# STM32G491 register map
File version: 2.8
CPU: CM4 r0p1, little endian, MPU, FPU, 4 interrupt priority bits
Registers are 32-bit, read-write, reset 0x0 unless marked. A register's access mark holds for its fields unless they carry their own. Offsets are from the block's base; [hi:lo] are bit positions; {n}, {i} and the like mark numbered series.

## FMAC — Filter Math Accelerator
Base 0x40021400
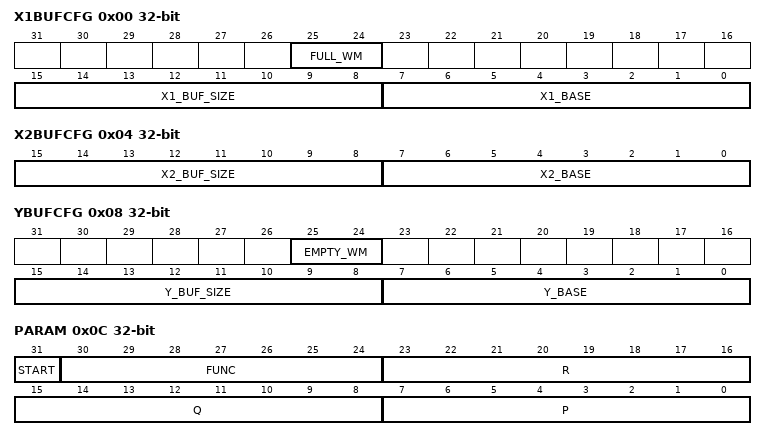
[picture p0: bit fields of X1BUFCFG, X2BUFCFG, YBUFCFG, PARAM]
0x00 X1BUFCFG — FMAC X1 Buffer Configuration register
  [25:24] FULL_WM, [15:8] X1_BUF_SIZE, [7:0] X1_BASE
0x04 X2BUFCFG — FMAC X2 Buffer Configuration register
  [15:8] X2_BUF_SIZE — X1_BUF_SIZE
  [7:0] X2_BASE — X1_BASE
0x08 YBUFCFG — FMAC Y Buffer Configuration register
  [25:24] EMPTY_WM
  [15:8] Y_BUF_SIZE — X1_BUF_SIZE
  [7:0] Y_BASE — X1_BASE
0x0C PARAM — FMAC Parameter register
  [31] START, [30:24] FUNC, [23:16] R, [15:8] Q, [7:0] P
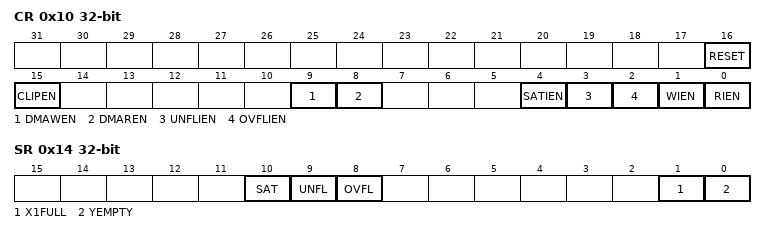
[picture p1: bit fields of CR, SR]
0x10 CR — FMAC Control register
  [16] RESET, [15] CLIPEN, [9] DMAWEN, [8] DMAREN, [4] SATIEN, [3] UNFLIEN, [2] OVFLIEN, [1] WIEN, [0] RIEN
0x14 SR ro — FMAC Status register
  [10] SAT, [9] UNFL, [8] OVFL, [1] X1FULL, [0] YEMPTY
0x18 WDATA wo — FMAC Write Data register
  [15:0] WDATA
0x1C RDATA ro — FMAC Read Data register
  [15:0] RDATA

## IWDG — WinWATCHDOG
Base 0x40003000
0x00 KR 16-bit wo — Key register
  [15:0] KEY — Key value (write only, read 0x0000)
    0x5555=Unlock (Enable access to PR, RLR and WINR registers); 0xAAAA=Feed watchdog with RLR register value; 0xCCCC=Start the watchdog
0x04 PR 16-bit — Prescaler register
  [2:0] PR — Prescaler divider
    0=DivideBy4 (Divider /4); 1=DivideBy8 (Divider /8); 2=DivideBy16 (Divider /16); 3=DivideBy32 (Divider /32); 4=DivideBy64 (Divider /64); 5=DivideBy128 (Divider /128); other=DivideBy256 (Divider /256)
0x08 RLR 16-bit reset 0xFFF — Reload register
  [11:0] RL — Watchdog counter reload value
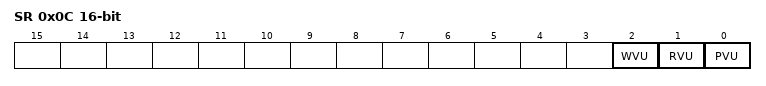
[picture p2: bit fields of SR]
0x0C SR 16-bit ro — Status register
  [2] WVU — Watchdog counter window value update
  [1] RVU — Watchdog counter reload value update
  [0] PVU — Watchdog prescaler value update
0x10 WINR 16-bit reset 0xFFF — Window register
  [11:0] WIN — Watchdog counter window value

## PWR — Power control
Base 0x40007000
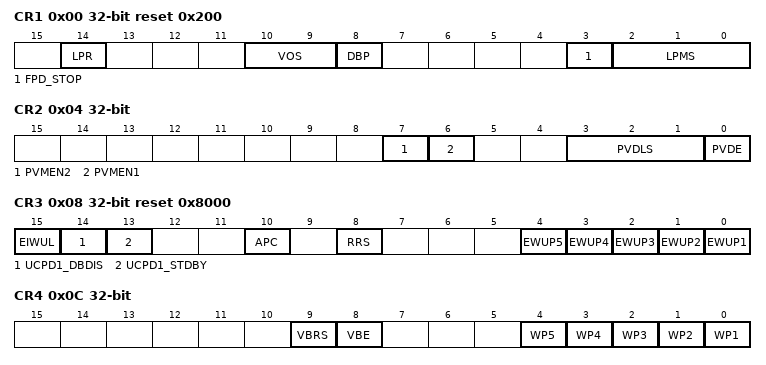
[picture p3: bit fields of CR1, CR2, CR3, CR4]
0x00 CR1 reset 0x200 — Power control register 1
  [14] LPR — Low-power run
  [10:9] VOS — Voltage scaling range selection
  [8] DBP — Disable backup domain write protection
  [3] FPD_STOP
  [2:0] LPMS — Low-power mode selection
0x04 CR2 — Power control register 2
  [7] PVMEN2 — Peripheral voltage monitoring 4 enable: V<sub>DDA</sub> vs. DAC 1MSPS /DAC 15MSPS min voltage.
  [6] PVMEN1 — Peripheral voltage monitoring 3 enable: V<sub>DDA</sub> vs. ADC/COMP min voltage 1.62V
  [3:1] PVDLS — Programmable voltage detector level selection.
  [0] PVDE — Programmable voltage detector enable
0x08 CR3 reset 0x8000 — Power control register 3
  [15] EIWUL — Enable internal wakeup line
  [14] UCPD1_DBDIS — USB Type-C and Power Delivery Dead Battery disable.
  [13] UCPD1_STDBY — UCPD1_STDBY USB Type-C and Power Delivery standby mode.
  [10] APC — Apply pull-up and pull-down configuration
  [8] RRS — SRAM2 retention in Standby mode
  [n-1] EWUP{n} (n=1..5) — Enable Wakeup pin WKUP{n}
0x0C CR4 — Power control register 4
  [9] VBRS — V<sub>BAT</sub> battery charging resistor selection
  [8] VBE — V<sub>BAT</sub> battery charging enable
  [n-1] WP{n} (n=1..5) — Wakeup pin WKUP{n} polarity
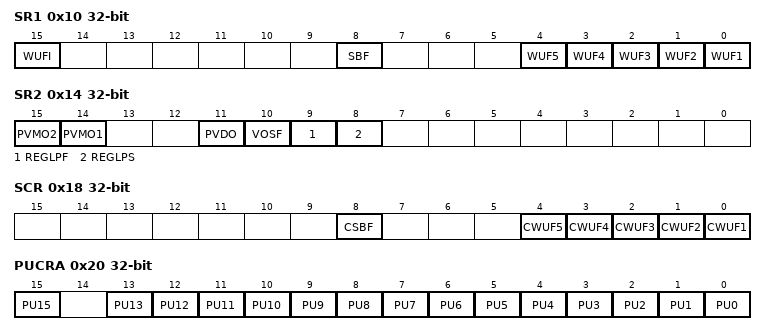
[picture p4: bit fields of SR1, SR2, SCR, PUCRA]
0x10 SR1 ro — Power status register 1
  [15] WUFI — Wakeup flag internal
  [8] SBF — Standby flag
  [n-1] WUF{n} (n=1..5) — Wakeup flag {n}
0x14 SR2 ro — Power status register 2
  [15] PVMO2 — Peripheral voltage monitoring output: V<sub>DDA</sub> vs. 1.8 V
  [14] PVMO1 — Peripheral voltage monitoring output: V<sub>DDA</sub> vs. 1.62 V
  [11] PVDO — Programmable voltage detector output
  [10] VOSF — Voltage scaling flag
  [9] REGLPF — Low-power regulator flag
  [8] REGLPS — Low-power regulator started
0x18 SCR wo — Power status clear register
  [8] CSBF — Clear standby flag
  [n-1] CWUF{n} (n=1..5) — Clear wakeup flag {n}
0x20 PUCRA — Power Port A pull-up control register
  [15] PU15 — Port A pull-up bit 15
  [n] PU{n} (n=0..13) — Port A pull-up bit y (y=0..13)
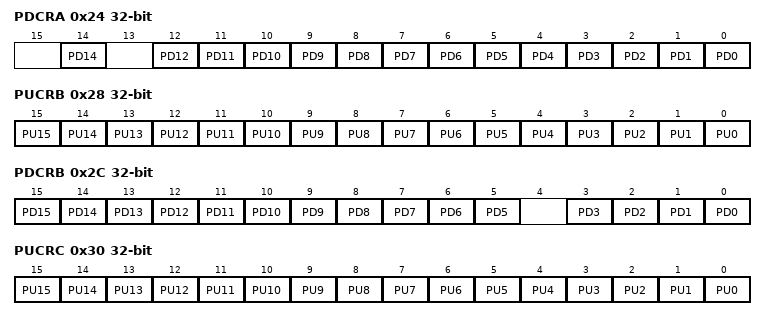
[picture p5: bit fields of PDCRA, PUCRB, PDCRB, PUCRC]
0x24 PDCRA — Power Port A pull-down control register
  [14] PD14 — Port A pull-down bit 14
  [n] PD{n} (n=0..12) — Port A pull-down bit y (y=0..12)
0x28 PUCRB — Power Port B pull-up control register
  [n] PU{n} (n=0..15) — Port B pull-up bit y (y=0..15)
0x2C PDCRB — Power Port B pull-down control register
  [n] PD{n} (n=5..15) — Port B pull-down bit y (y=5..15)
  [n] PD{n} (n=0..3) — Port B pull-down bit y (y=0..3)
0x30 PUCRC — Power Port C pull-up control register
  [n] PU{n} (n=0..15) — Port C pull-up bit y (y=0..15)
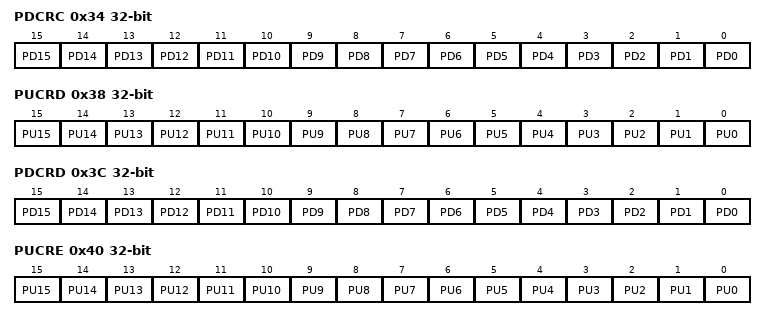
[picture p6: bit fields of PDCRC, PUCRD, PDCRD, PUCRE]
0x34 PDCRC — Power Port C pull-down control register
  [n] PD{n} (n=0..15) — Port C pull-down bit y (y=0..15)
0x38 PUCRD — Power Port D pull-up control register
  [n] PU{n} (n=0..15) — Port D pull-up bit y (y=0..15)
0x3C PDCRD — Power Port D pull-down control register
  [n] PD{n} (n=0..15) — Port D pull-down bit y (y=0..15)
0x40 PUCRE — Power Port E pull-up control register
  [n] PU{n} (n=0..15) — Port E pull-up bit y (y=0..15)
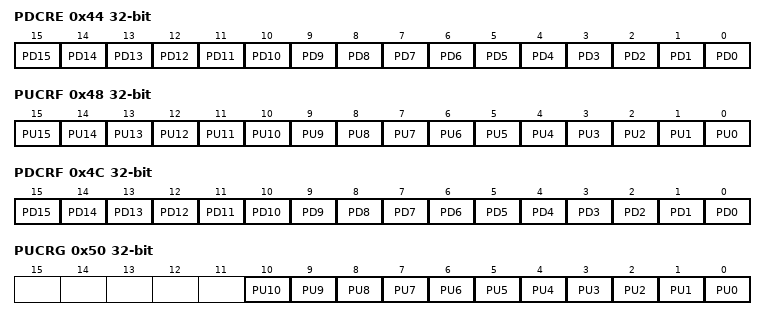
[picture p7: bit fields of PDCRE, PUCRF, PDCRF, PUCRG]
0x44 PDCRE — Power Port E pull-down control register
  [n] PD{n} (n=0..15) — Port E pull-down bit y (y=0..15)
0x48 PUCRF — Power Port F pull-up control register
  [n] PU{n} (n=0..15) — Port F pull-up bit y (y=0..15)
0x4C PDCRF — Power Port F pull-down control register
  [n] PD{n} (n=0..15) — Port F pull-down bit y (y=0..15)
0x50 PUCRG — Power Port G pull-up control register
  [n] PU{n} (n=0..10) — Port G pull-up bit y (y=0..10)
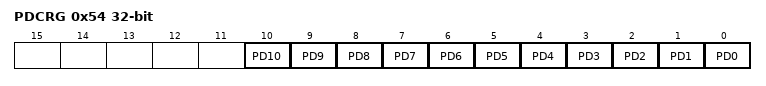
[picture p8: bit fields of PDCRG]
0x54 PDCRG — Power Port G pull-down control register
  [n] PD{n} (n=0..10) — Port G pull-down bit y (y=0..10)
0x80 CR5 reset 0x100 — Power control register
  [8] R1MODE — Main regular range 1 mode
